# LM3S5749 register map
File version: 7944
Registers are 32-bit, read-write, no defined reset value unless marked. A register's access mark holds for its fields unless they carry their own. Offsets are from the block's base; [hi:lo] are bit positions; {n}, {i} and the like mark numbered series.

## SYSCTL — Register map for SYSCTL peripheral
Base 0x400FE000; register names take the prefix SYSCTL
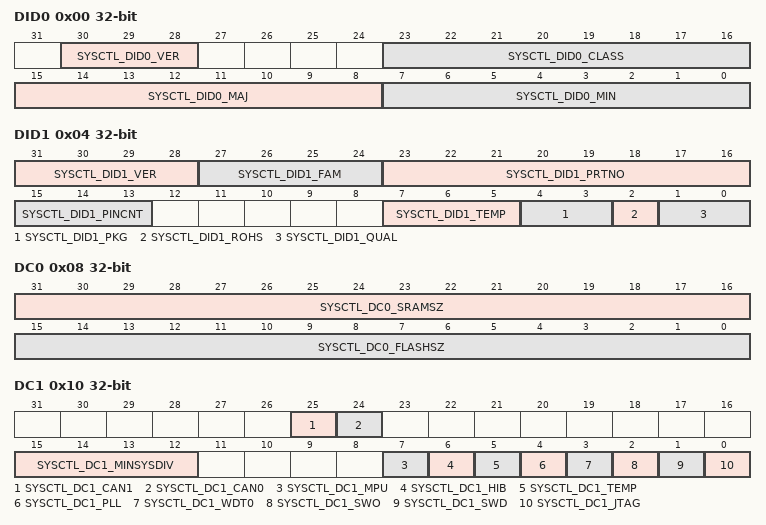
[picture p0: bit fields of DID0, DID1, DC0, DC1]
0x00 DID0 — Device Identification 0
  [30:28] SYSCTL_DID0_VER — DID0 Version
    1=Second version of the DID0 register format
  [23:16] SYSCTL_DID0_CLASS — Device Class
    3=SYSCTL_DID0_CLASS_DUSTDEVIL (Stellaris(R) DustDevil-class devices)
  [15:8] SYSCTL_DID0_MAJ — Major Revision
    0=SYSCTL_DID0_MAJ_REVA (Revision A (initial device)); 1=SYSCTL_DID0_MAJ_REVB (Revision B (first base layer revision)); 2=SYSCTL_DID0_MAJ_REVC (Revision C (second base layer revision))
  [7:0] SYSCTL_DID0_MIN — Minor Revision
    0=Initial device, or a major revision update; 1=First metal layer change; 2=Second metal layer change
0x04 DID1 — Device Identification 1
  [31:28] SYSCTL_DID1_VER — DID1 Version
    1=Second version of the DID1 register format
  [27:24] SYSCTL_DID1_FAM — Family
    0=SYSCTL_DID1_FAM_STELLARIS (Stellaris family of microcontollers, that is, all devices with external part numbers starting with LM3S)
  [23:16] SYSCTL_DID1_PRTNO — Part Number
    167=LM3S5749
  [15:13] SYSCTL_DID1_PINCNT — Package Pin Count
    2=100-pin package
  [7:5] SYSCTL_DID1_TEMP — Temperature Range
    0=SYSCTL_DID1_TEMP_C (Commercial temperature range (0C to 70C)); 1=SYSCTL_DID1_TEMP_I (Industrial temperature range (-40C to 85C)); 2=SYSCTL_DID1_TEMP_E (Extended temperature range (-40C to 105C))
  [4:3] SYSCTL_DID1_PKG — Package Type
    0=SYSCTL_DID1_PKG_SOIC (SOIC package); 1=SYSCTL_DID1_PKG_QFP (LQFP package); 2=SYSCTL_DID1_PKG_BGA (BGA package)
  [2] SYSCTL_DID1_ROHS — RoHS-Compliance
  [1:0] SYSCTL_DID1_QUAL — Qualification Status
    0=SYSCTL_DID1_QUAL_ES (Engineering Sample (unqualified)); 1=SYSCTL_DID1_QUAL_PP (Pilot Production (unqualified)); 2=SYSCTL_DID1_QUAL_FQ (Fully Qualified)
0x08 DC0 — Device Capabilities 0
  [31:16] SYSCTL_DC0_SRAMSZ — SRAM Size
    255=SYSCTL_DC0_SRAMSZ_64KB (64 KB of SRAM)
  [15:0] SYSCTL_DC0_FLASHSZ — Flash Size
    63=SYSCTL_DC0_FLASHSZ_128K (128 KB of Flash)
0x10 DC1 — Device Capabilities 1
  [25] SYSCTL_DC1_CAN1 — CAN Module 1 Present
  [24] SYSCTL_DC1_CAN0 — CAN Module 0 Present
  [15:12] SYSCTL_DC1_MINSYSDIV — System Clock Divider
    3=Specifies a 50-MHz CPU clock with a PLL divider of 4
  [7] SYSCTL_DC1_MPU — MPU Present
  [6] SYSCTL_DC1_HIB — Hibernation Module Present
  [5] SYSCTL_DC1_TEMP — Temp Sensor Present
  [4] SYSCTL_DC1_PLL — PLL Present
  [3] SYSCTL_DC1_WDT0 — Watchdog Timer 0 Present
  [2] SYSCTL_DC1_SWO — SWO Trace Port Present
  [1] SYSCTL_DC1_SWD — SWD Present
  [0] SYSCTL_DC1_JTAG — JTAG Present
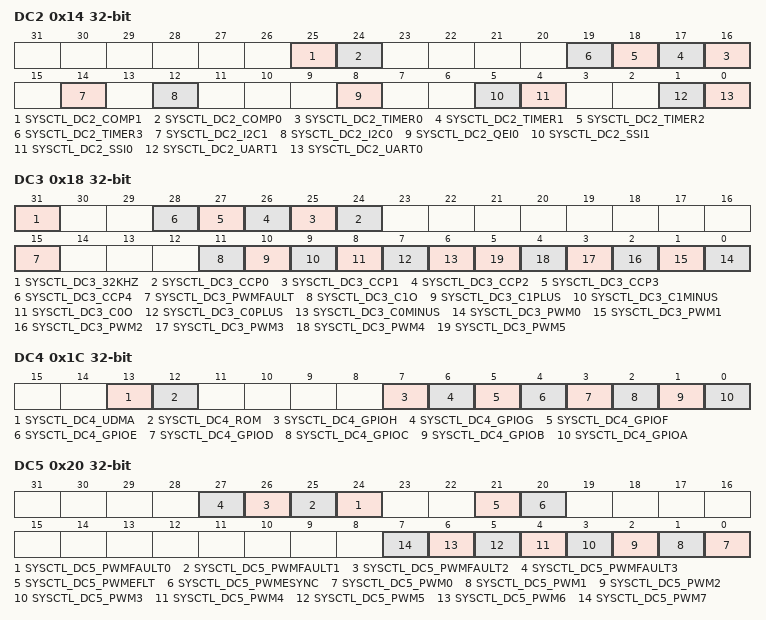
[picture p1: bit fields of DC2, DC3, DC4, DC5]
0x14 DC2 — Device Capabilities 2
  [25] SYSCTL_DC2_COMP1 — Analog Comparator 1 Present
  [24] SYSCTL_DC2_COMP0 — Analog Comparator 0 Present
  [n+16] SYSCTL_DC2_TIMER{n} (n=0..3) — Timer Module {n} Present
  [14] SYSCTL_DC2_I2C1 — I2C Module 1 Present
  [12] SYSCTL_DC2_I2C0 — I2C Module 0 Present
  [8] SYSCTL_DC2_QEI0 — QEI Module 0 Present
  [5] SYSCTL_DC2_SSI1 — SSI Module 1 Present
  [4] SYSCTL_DC2_SSI0 — SSI Module 0 Present
  [1] SYSCTL_DC2_UART1 — UART Module 1 Present
  [0] SYSCTL_DC2_UART0 — UART Module 0 Present
0x18 DC3 — Device Capabilities 3
  [31] SYSCTL_DC3_32KHZ — 32KHz Input Clock Available
  [n+24] SYSCTL_DC3_CCP{n} (n=0..4) — CCP{n} Pin Present
  [15] SYSCTL_DC3_PWMFAULT — PWM Fault Pin Present
  [11] SYSCTL_DC3_C1O — C1o Pin Present
  [10] SYSCTL_DC3_C1PLUS — C1+ Pin Present
  [9] SYSCTL_DC3_C1MINUS — C1- Pin Present
  [8] SYSCTL_DC3_C0O — C0o Pin Present
  [7] SYSCTL_DC3_C0PLUS — C0+ Pin Present
  [6] SYSCTL_DC3_C0MINUS — C0- Pin Present
  [n] SYSCTL_DC3_PWM{n} (n=0..5) — PWM{n} Pin Present
0x1C DC4 — Device Capabilities 4
  [13] SYSCTL_DC4_UDMA — Micro-DMA Module Present
  [12] SYSCTL_DC4_ROM — Internal Code ROM Present
  [7] SYSCTL_DC4_GPIOH — GPIO Port H Present
  [6] SYSCTL_DC4_GPIOG — GPIO Port G Present
  [5] SYSCTL_DC4_GPIOF — GPIO Port F Present
  [4] SYSCTL_DC4_GPIOE — GPIO Port E Present
  [3] SYSCTL_DC4_GPIOD — GPIO Port D Present
  [2] SYSCTL_DC4_GPIOC — GPIO Port C Present
  [1] SYSCTL_DC4_GPIOB — GPIO Port B Present
  [0] SYSCTL_DC4_GPIOA — GPIO Port A Present
0x20 DC5 — Device Capabilities 5
  [n+24] SYSCTL_DC5_PWMFAULT{n} (n=0..3) — PWM Fault {n} Pin Present
  [21] SYSCTL_DC5_PWMEFLT — PWM Extended Fault Active
  [20] SYSCTL_DC5_PWMESYNC — PWM Extended SYNC Active
  [n] SYSCTL_DC5_PWM{n} (n=0..7) — PWM{n} Pin Present
0x24 DC6 — Device Capabilities 6
  [1:0] SYSCTL_DC6_USB0 — USB Module 0 Present
    2=SYSCTL_DC6_USB0_HOSTDEV (USB is Device or Host)
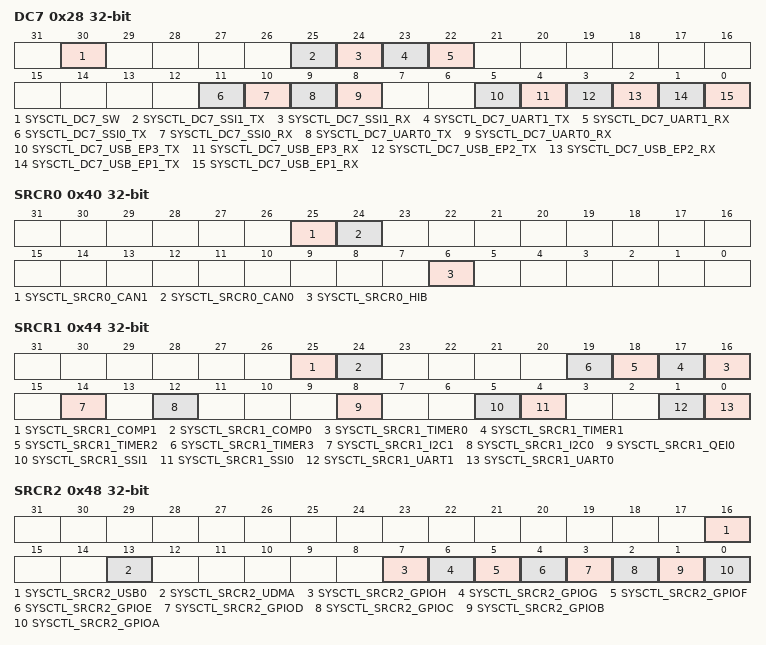
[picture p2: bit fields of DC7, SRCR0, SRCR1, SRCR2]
0x28 DC7 — Device Capabilities 7
  [30] SYSCTL_DC7_SW — Software transfer on uDMA Ch30
  [25] SYSCTL_DC7_SSI1_TX — SSI1 TX on uDMA Ch25
  [24] SYSCTL_DC7_SSI1_RX — SSI1 RX on uDMA Ch24
  [23] SYSCTL_DC7_UART1_TX — UART1 TX on uDMA Ch23
  [22] SYSCTL_DC7_UART1_RX — UART1 RX on uDMA Ch22
  [11] SYSCTL_DC7_SSI0_TX — SSI0 TX on uDMA Ch11
  [10] SYSCTL_DC7_SSI0_RX — SSI0 RX on uDMA Ch10
  [9] SYSCTL_DC7_UART0_TX — UART0 TX on uDMA Ch9
  [8] SYSCTL_DC7_UART0_RX — UART0 RX on uDMA Ch8
  [5] SYSCTL_DC7_USB_EP3_TX — USB EP3 TX on uDMA Ch5
  [4] SYSCTL_DC7_USB_EP3_RX — USB EP3 RX on uDMA Ch4
  [3] SYSCTL_DC7_USB_EP2_TX — USB EP2 TX on uDMA Ch3
  [2] SYSCTL_DC7_USB_EP2_RX — USB EP2 RX on uDMA Ch2
  [1] SYSCTL_DC7_USB_EP1_TX — USB EP1 TX on uDMA Ch1
  [0] SYSCTL_DC7_USB_EP1_RX — USB EP1 RX on uDMA Ch0
0x30 PBORCTL — Brown-Out Reset Control
  [1] SYSCTL_PBORCTL_BORIOR — BOR Interrupt or Reset
0x34 LDOPCTL — LDO Power Control
  [5:0] SYSCTL_LDOPCTL — LDO Output Voltage
    0=SYSCTL_LDOPCTL_2_50V (2.50); 1=SYSCTL_LDOPCTL_2_45V (2.45); 2=SYSCTL_LDOPCTL_2_40V (2.40); 3=SYSCTL_LDOPCTL_2_35V (2.35); 4=SYSCTL_LDOPCTL_2_30V (2.30); 5=SYSCTL_LDOPCTL_2_25V (2.25); 27=SYSCTL_LDOPCTL_2_75V (2.75); 28=SYSCTL_LDOPCTL_2_70V (2.70); 29=SYSCTL_LDOPCTL_2_65V (2.65); 30=SYSCTL_LDOPCTL_2_60V (2.60); 31=SYSCTL_LDOPCTL_2_55V (2.55)
0x40 SRCR0 — Software Reset Control 0
  [25] SYSCTL_SRCR0_CAN1 — CAN1 Reset Control
  [24] SYSCTL_SRCR0_CAN0 — CAN0 Reset Control
  [6] SYSCTL_SRCR0_HIB — HIB Reset Control
0x44 SRCR1 — Software Reset Control 1
  [25] SYSCTL_SRCR1_COMP1 — Analog Comp 1 Reset Control
  [24] SYSCTL_SRCR1_COMP0 — Analog Comp 0 Reset Control
  [n+16] SYSCTL_SRCR1_TIMER{n} (n=0..3) — Timer {n} Reset Control
  [14] SYSCTL_SRCR1_I2C1 — I2C1 Reset Control
  [12] SYSCTL_SRCR1_I2C0 — I2C0 Reset Control
  [8] SYSCTL_SRCR1_QEI0 — QEI0 Reset Control
  [5] SYSCTL_SRCR1_SSI1 — SSI1 Reset Control
  [4] SYSCTL_SRCR1_SSI0 — SSI0 Reset Control
  [1] SYSCTL_SRCR1_UART1 — UART1 Reset Control
  [0] SYSCTL_SRCR1_UART0 — UART0 Reset Control
0x48 SRCR2 — Software Reset Control 2
  [16] SYSCTL_SRCR2_USB0 — USB0 Reset Control
  [13] SYSCTL_SRCR2_UDMA — Micro-DMA Reset Control
  [7] SYSCTL_SRCR2_GPIOH — Port H Reset Control
  [6] SYSCTL_SRCR2_GPIOG — Port G Reset Control
  [5] SYSCTL_SRCR2_GPIOF — Port F Reset Control
  [4] SYSCTL_SRCR2_GPIOE — Port E Reset Control
  [3] SYSCTL_SRCR2_GPIOD — Port D Reset Control
  [2] SYSCTL_SRCR2_GPIOC — Port C Reset Control
  [1] SYSCTL_SRCR2_GPIOB — Port B Reset Control
  [0] SYSCTL_SRCR2_GPIOA — Port A Reset Control
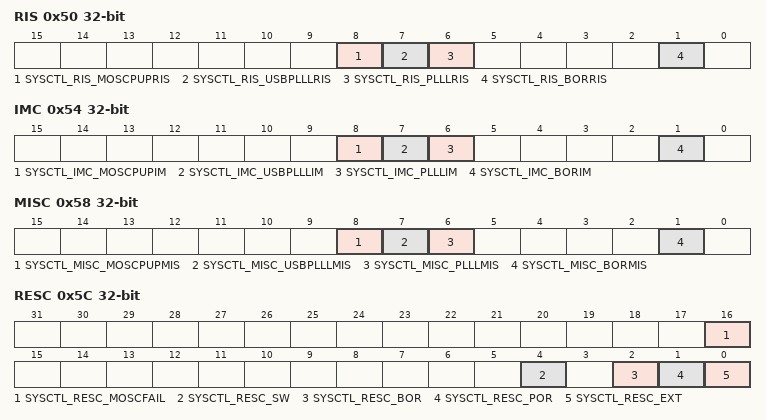
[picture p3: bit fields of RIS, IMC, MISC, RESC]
0x50 RIS — Raw Interrupt Status
  [8] SYSCTL_RIS_MOSCPUPRIS — MOSC Power Up Raw Interrupt Status
  [7] SYSCTL_RIS_USBPLLLRIS — USB PLL Lock Raw Interrupt Status
  [6] SYSCTL_RIS_PLLLRIS — PLL Lock Raw Interrupt Status
  [1] SYSCTL_RIS_BORRIS — Brown-Out Reset Raw Interrupt Status
0x54 IMC — Interrupt Mask Control
  [8] SYSCTL_IMC_MOSCPUPIM — MOSC Power Up Interrupt Mask
  [7] SYSCTL_IMC_USBPLLLIM — USB PLL Lock Interrupt Mask
  [6] SYSCTL_IMC_PLLLIM — PLL Lock Interrupt Mask
  [1] SYSCTL_IMC_BORIM — Brown-Out Reset Interrupt Mask
0x58 MISC — Masked Interrupt Status and Clear
  [8] SYSCTL_MISC_MOSCPUPMIS — MOSC Power Up Masked Interrupt Status
  [7] SYSCTL_MISC_USBPLLLMIS — USB PLL Lock Masked Interrupt Status
  [6] SYSCTL_MISC_PLLLMIS — PLL Lock Masked Interrupt Status
  [1] SYSCTL_MISC_BORMIS — BOR Masked Interrupt Status
0x5C RESC — Reset Cause
  [16] SYSCTL_RESC_MOSCFAIL — MOSC Failure Reset
  [4] SYSCTL_RESC_SW — Software Reset
  [2] SYSCTL_RESC_BOR — Brown-Out Reset
  [1] SYSCTL_RESC_POR — Power-On Reset
  [0] SYSCTL_RESC_EXT — External Reset
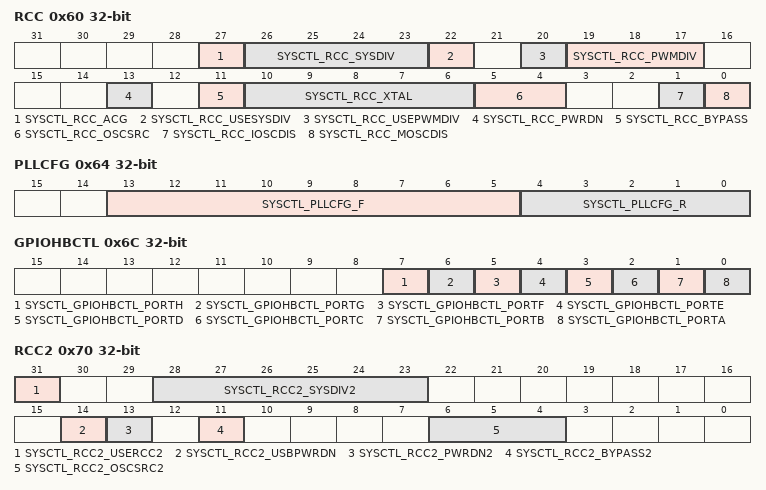
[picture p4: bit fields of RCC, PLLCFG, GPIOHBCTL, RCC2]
0x60 RCC — Run-Mode Clock Configuration
  [27] SYSCTL_RCC_ACG — Auto Clock Gating
  [26:23] SYSCTL_RCC_SYSDIV — System Clock Divisor
    {v}=System clock /{v+1} (v=1..15)
  [22] SYSCTL_RCC_USESYSDIV — Enable System Clock Divider
  [20] SYSCTL_RCC_USEPWMDIV — Enable PWM Clock Divisor
  [19:17] SYSCTL_RCC_PWMDIV — PWM Unit Clock Divisor
    0=PWM clock /2; 1=PWM clock /4; 2=PWM clock /8; 3=PWM clock /16; 4=PWM clock /32; 5=PWM clock /64
  [13] SYSCTL_RCC_PWRDN — PLL Power Down
  [11] SYSCTL_RCC_BYPASS — PLL Bypass
  [10:6] SYSCTL_RCC_XTAL — Crystal Value
    0=SYSCTL_RCC_XTAL_1MHZ (1 MHz); 1=SYSCTL_RCC_XTAL_1_84MHZ (1.8432 MHz); 2=SYSCTL_RCC_XTAL_2MHZ (2 MHz); 3=SYSCTL_RCC_XTAL_2_45MHZ (2.4576 MHz); 4=SYSCTL_RCC_XTAL_3_57MHZ (3.579545 MHz); 5=SYSCTL_RCC_XTAL_3_68MHZ (3.6864 MHz); 6=SYSCTL_RCC_XTAL_4MHZ (4 MHz); 7=SYSCTL_RCC_XTAL_4_09MHZ (4.096 MHz); 8=SYSCTL_RCC_XTAL_4_91MHZ (4.9152 MHz); 9=SYSCTL_RCC_XTAL_5MHZ (5 MHz); 10=SYSCTL_RCC_XTAL_5_12MHZ (5.12 MHz); 11=SYSCTL_RCC_XTAL_6MHZ (6 MHz); 12=SYSCTL_RCC_XTAL_6_14MHZ (6.144 MHz); 13=SYSCTL_RCC_XTAL_7_37MHZ (7.3728 MHz); 14=SYSCTL_RCC_XTAL_8MHZ (8 MHz); 15=SYSCTL_RCC_XTAL_8_19MHZ (8.192 MHz); 16=SYSCTL_RCC_XTAL_10MHZ (10 MHz); 17=SYSCTL_RCC_XTAL_12MHZ (12 MHz); 18=SYSCTL_RCC_XTAL_12_2MHZ (12.288 MHz); 19=SYSCTL_RCC_XTAL_13_5MHZ (13.56 MHz); 20=SYSCTL_RCC_XTAL_14_3MHZ (14.31818 MHz); 21=SYSCTL_RCC_XTAL_16MHZ (16 MHz); 22=SYSCTL_RCC_XTAL_16_3MHZ (16.384 MHz)
  [5:4] SYSCTL_RCC_OSCSRC — Oscillator Source
    0=SYSCTL_RCC_OSCSRC_MAIN (MOSC); 1=SYSCTL_RCC_OSCSRC_INT (IOSC); 2=SYSCTL_RCC_OSCSRC_INT4 (IOSC/4); 3=30 kHz
  [1] SYSCTL_RCC_IOSCDIS — Internal Oscillator Disable
  [0] SYSCTL_RCC_MOSCDIS — Main Oscillator Disable
0x64 PLLCFG — XTAL to PLL Translation
  [13:5] SYSCTL_PLLCFG_F — PLL F Value
  [4:0] SYSCTL_PLLCFG_R — PLL R Value
0x6C GPIOHBCTL — GPIO High-Performance Bus Control
  [7] SYSCTL_GPIOHBCTL_PORTH — Port H Advanced High-Performance Bus
  [6] SYSCTL_GPIOHBCTL_PORTG — Port G Advanced High-Performance Bus
  [5] SYSCTL_GPIOHBCTL_PORTF — Port F Advanced High-Performance Bus
  [4] SYSCTL_GPIOHBCTL_PORTE — Port E Advanced High-Performance Bus
  [3] SYSCTL_GPIOHBCTL_PORTD — Port D Advanced High-Performance Bus
  [2] SYSCTL_GPIOHBCTL_PORTC — Port C Advanced High-Performance Bus
  [1] SYSCTL_GPIOHBCTL_PORTB — Port B Advanced High-Performance Bus
  [0] SYSCTL_GPIOHBCTL_PORTA — Port A Advanced High-Performance Bus
0x70 RCC2 — Run-Mode Clock Configuration 2
  [31] SYSCTL_RCC2_USERCC2 — Use RCC2
  [28:23] SYSCTL_RCC2_SYSDIV2 — System Clock Divisor 2
    {v}=System clock /{v+1} (v=1..63)
  [14] SYSCTL_RCC2_USBPWRDN — Power-Down USB PLL
  [13] SYSCTL_RCC2_PWRDN2 — Power-Down PLL 2
  [11] SYSCTL_RCC2_BYPASS2 — PLL Bypass 2
  [6:4] SYSCTL_RCC2_OSCSRC2 — Oscillator Source 2
    0=SYSCTL_RCC2_OSCSRC2_MO (MOSC); 1=SYSCTL_RCC2_OSCSRC2_IO (PIOSC); 2=SYSCTL_RCC2_OSCSRC2_IO4 (PIOSC/4); 3=30 kHz; 7=32.768 kHz
0x7C MOSCCTL — Main Oscillator Control
  [0] SYSCTL_MOSCCTL_CVAL — Clock Validation for MOSC
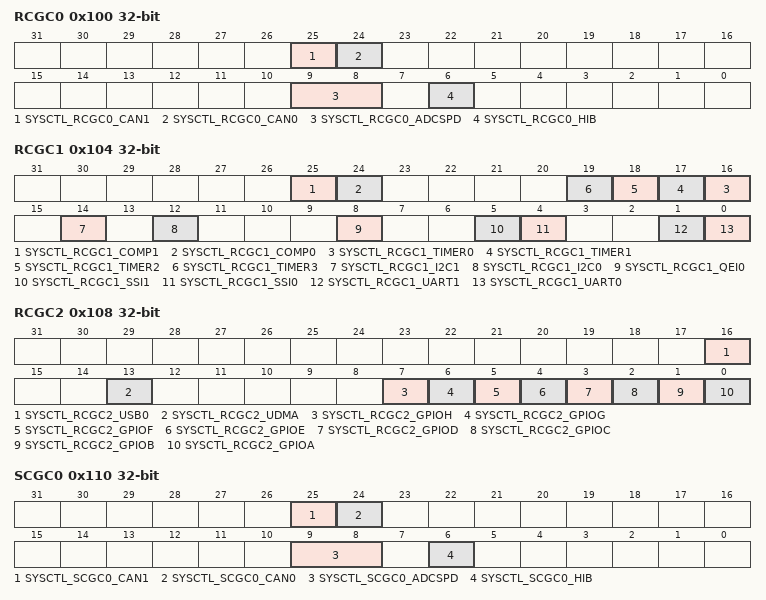
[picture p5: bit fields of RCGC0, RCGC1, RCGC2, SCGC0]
0x100 RCGC0 — Run Mode Clock Gating Control Register 0
  [25] SYSCTL_RCGC0_CAN1 — CAN1 Clock Gating Control
  [24] SYSCTL_RCGC0_CAN0 — CAN0 Clock Gating Control
  [9:8] SYSCTL_RCGC0_ADCSPD — ADC Sample Speed
    0=SYSCTL_RCGC0_ADCSPD125K (125K samples/second); 1=SYSCTL_RCGC0_ADCSPD250K (250K samples/second); 2=SYSCTL_RCGC0_ADCSPD500K (500K samples/second); 3=SYSCTL_RCGC0_ADCSPD1M (1M samples/second)
  [6] SYSCTL_RCGC0_HIB — HIB Clock Gating Control
0x104 RCGC1 — Run Mode Clock Gating Control Register 1
  [25] SYSCTL_RCGC1_COMP1 — Analog Comparator 1 Clock Gating
  [24] SYSCTL_RCGC1_COMP0 — Analog Comparator 0 Clock Gating
  [n+16] SYSCTL_RCGC1_TIMER{n} (n=0..3) — Timer {n} Clock Gating Control
  [14] SYSCTL_RCGC1_I2C1 — I2C1 Clock Gating Control
  [12] SYSCTL_RCGC1_I2C0 — I2C0 Clock Gating Control
  [8] SYSCTL_RCGC1_QEI0 — QEI0 Clock Gating Control
  [5] SYSCTL_RCGC1_SSI1 — SSI1 Clock Gating Control
  [4] SYSCTL_RCGC1_SSI0 — SSI0 Clock Gating Control
  [1] SYSCTL_RCGC1_UART1 — UART1 Clock Gating Control
  [0] SYSCTL_RCGC1_UART0 — UART0 Clock Gating Control
0x108 RCGC2 — Run Mode Clock Gating Control Register 2
  [16] SYSCTL_RCGC2_USB0 — USB0 Clock Gating Control
  [13] SYSCTL_RCGC2_UDMA — Micro-DMA Clock Gating Control
  [7] SYSCTL_RCGC2_GPIOH — Port H Clock Gating Control
  [6] SYSCTL_RCGC2_GPIOG — Port G Clock Gating Control
  [5] SYSCTL_RCGC2_GPIOF — Port F Clock Gating Control
  [4] SYSCTL_RCGC2_GPIOE — Port E Clock Gating Control
  [3] SYSCTL_RCGC2_GPIOD — Port D Clock Gating Control
  [2] SYSCTL_RCGC2_GPIOC — Port C Clock Gating Control
  [1] SYSCTL_RCGC2_GPIOB — Port B Clock Gating Control
  [0] SYSCTL_RCGC2_GPIOA — Port A Clock Gating Control
0x110 SCGC0 — Sleep Mode Clock Gating Control Register 0
  [25] SYSCTL_SCGC0_CAN1 — CAN1 Clock Gating Control
  [24] SYSCTL_SCGC0_CAN0 — CAN0 Clock Gating Control
  [9:8] SYSCTL_SCGC0_ADCSPD — ADC Sample Speed
    0=SYSCTL_SCGC0_ADCSPD125K (125K samples/second); 1=SYSCTL_SCGC0_ADCSPD250K (250K samples/second); 2=SYSCTL_SCGC0_ADCSPD500K (500K samples/second); 3=SYSCTL_SCGC0_ADCSPD1M (1M samples/second)
  [6] SYSCTL_SCGC0_HIB — HIB Clock Gating Control
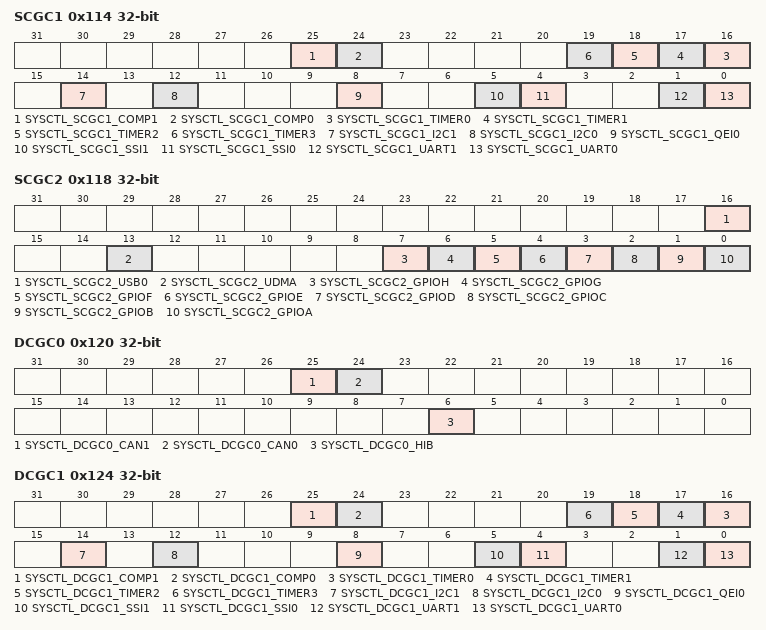
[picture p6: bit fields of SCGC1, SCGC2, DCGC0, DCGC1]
0x114 SCGC1 — Sleep Mode Clock Gating Control Register 1
  [25] SYSCTL_SCGC1_COMP1 — Analog Comparator 1 Clock Gating
  [24] SYSCTL_SCGC1_COMP0 — Analog Comparator 0 Clock Gating
  [n+16] SYSCTL_SCGC1_TIMER{n} (n=0..3) — Timer {n} Clock Gating Control
  [14] SYSCTL_SCGC1_I2C1 — I2C1 Clock Gating Control
  [12] SYSCTL_SCGC1_I2C0 — I2C0 Clock Gating Control
  [8] SYSCTL_SCGC1_QEI0 — QEI0 Clock Gating Control
  [5] SYSCTL_SCGC1_SSI1 — SSI1 Clock Gating Control
  [4] SYSCTL_SCGC1_SSI0 — SSI0 Clock Gating Control
  [1] SYSCTL_SCGC1_UART1 — UART1 Clock Gating Control
  [0] SYSCTL_SCGC1_UART0 — UART0 Clock Gating Control
0x118 SCGC2 — Sleep Mode Clock Gating Control Register 2
  [16] SYSCTL_SCGC2_USB0 — USB0 Clock Gating Control
  [13] SYSCTL_SCGC2_UDMA — Micro-DMA Clock Gating Control
  [7] SYSCTL_SCGC2_GPIOH — Port H Clock Gating Control
  [6] SYSCTL_SCGC2_GPIOG — Port G Clock Gating Control
  [5] SYSCTL_SCGC2_GPIOF — Port F Clock Gating Control
  [4] SYSCTL_SCGC2_GPIOE — Port E Clock Gating Control
  [3] SYSCTL_SCGC2_GPIOD — Port D Clock Gating Control
  [2] SYSCTL_SCGC2_GPIOC — Port C Clock Gating Control
  [1] SYSCTL_SCGC2_GPIOB — Port B Clock Gating Control
  [0] SYSCTL_SCGC2_GPIOA — Port A Clock Gating Control
0x120 DCGC0 — Deep Sleep Mode Clock Gating Control Register 0
  [25] SYSCTL_DCGC0_CAN1 — CAN1 Clock Gating Control
  [24] SYSCTL_DCGC0_CAN0 — CAN0 Clock Gating Control
  [6] SYSCTL_DCGC0_HIB — HIB Clock Gating Control
0x124 DCGC1 — Deep-Sleep Mode Clock Gating Control Register 1
  [25] SYSCTL_DCGC1_COMP1 — Analog Comparator 1 Clock Gating
  [24] SYSCTL_DCGC1_COMP0 — Analog Comparator 0 Clock Gating
  [n+16] SYSCTL_DCGC1_TIMER{n} (n=0..3) — Timer {n} Clock Gating Control
  [14] SYSCTL_DCGC1_I2C1 — I2C1 Clock Gating Control
  [12] SYSCTL_DCGC1_I2C0 — I2C0 Clock Gating Control
  [8] SYSCTL_DCGC1_QEI0 — QEI0 Clock Gating Control
  [5] SYSCTL_DCGC1_SSI1 — SSI1 Clock Gating Control
  [4] SYSCTL_DCGC1_SSI0 — SSI0 Clock Gating Control
  [1] SYSCTL_DCGC1_UART1 — UART1 Clock Gating Control
  [0] SYSCTL_DCGC1_UART0 — UART0 Clock Gating Control
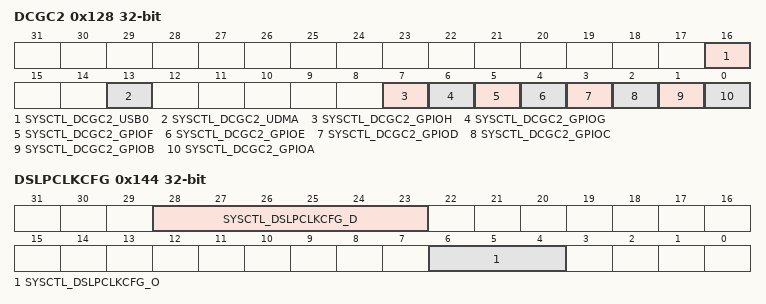
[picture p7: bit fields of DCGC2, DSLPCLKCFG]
0x128 DCGC2 — Deep Sleep Mode Clock Gating Control Register 2
  [16] SYSCTL_DCGC2_USB0 — USB0 Clock Gating Control
  [13] SYSCTL_DCGC2_UDMA — Micro-DMA Clock Gating Control
  [7] SYSCTL_DCGC2_GPIOH — Port H Clock Gating Control
  [6] SYSCTL_DCGC2_GPIOG — Port G Clock Gating Control
  [5] SYSCTL_DCGC2_GPIOF — Port F Clock Gating Control
  [4] SYSCTL_DCGC2_GPIOE — Port E Clock Gating Control
  [3] SYSCTL_DCGC2_GPIOD — Port D Clock Gating Control
  [2] SYSCTL_DCGC2_GPIOC — Port C Clock Gating Control
  [1] SYSCTL_DCGC2_GPIOB — Port B Clock Gating Control
  [0] SYSCTL_DCGC2_GPIOA — Port A Clock Gating Control
0x144 DSLPCLKCFG — Deep Sleep Clock Configuration
  [28:23] SYSCTL_DSLPCLKCFG_D — Divider Field Override
    {v}=System clock /{v+1} (v=0..63)
  [6:4] SYSCTL_DSLPCLKCFG_O — Clock Source
    0=SYSCTL_DSLPCLKCFG_O_IGN (MOSC); 1=SYSCTL_DSLPCLKCFG_O_IO (PIOSC); 3=30 kHz; 7=32.768 kHz
